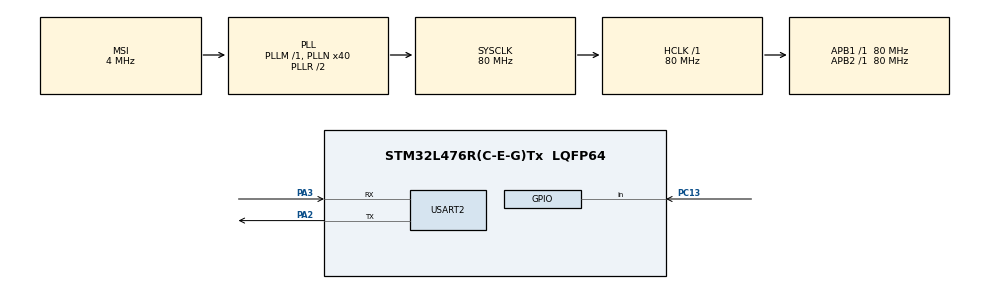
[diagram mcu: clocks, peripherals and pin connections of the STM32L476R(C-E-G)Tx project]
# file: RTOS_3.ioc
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FREERTOS.BinarySemaphores01=BinSem,Dynamic,NULL
FREERTOS.Tasks01=NormalTask,0,128,StartNormalTask,Default,NULL,Dynamic,NULL,NULL;HighTask,1,128,StartHighTask,Default,NULL,Dynamic,NULL,NULL;LowTask,-1,128,StartLowTask,Default,NULL,Dynamic,NULL,NULL
Mcu.Family=STM32L4
Mcu.Name=STM32L476R(C-E-G)Tx
Mcu.Package=LQFP64
NVIC.PriorityGroup=NVIC_PRIORITYGROUP_4
NVIC.TIM1_UP_TIM16_IRQn=true\:0\:0\:false\:false\:true\:false\:false\:true
NVIC.TimeBase=TIM1_UP_TIM16_IRQn
NVIC.TimeBaseIP=TIM1
PA2.Mode=Asynchronous
PA2.Signal=USART2_TX
PA3.Mode=Asynchronous
PA3.Signal=USART2_RX
PC13.Signal=GPIO_Input
ProjectManager.HeapSize=0x200
ProjectManager.StackSize=0x400
ProjectManager.TargetToolchain=TrueSTUDIO
RCC.AHBFreq_Value=80000000
RCC.APB1Freq_Value=80000000
RCC.APB1TimFreq_Value=80000000
RCC.APB2Freq_Value=80000000
RCC.APB2TimFreq_Value=80000000
RCC.CortexFreq_Value=80000000
RCC.HCLKFreq_Value=80000000
RCC.HSE_VALUE=8000000
RCC.HSI_VALUE=16000000
RCC.LSE_VALUE=32768
RCC.MSI_VALUE=4000000
RCC.PLLN=40
RCC.SYSCLKFreq_VALUE=80000000
RCC.SYSCLKSource=RCC_SYSCLKSOURCE_PLLCLK
RCC.VCOOutputFreq_Value=160000000
USART2.VirtualMode-Asynchronous=VM_ASYNC
VP_FREERTOS_VS_CMSIS_V1.Mode=CMSIS_V1
VP_SYS_VS_tim1.Mode=TIM1
board=custom

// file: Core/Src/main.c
/* USER CODE BEGIN Header */
/**
  ******************************************************************************
  * @file           : main.c
  * @brief          : Main program body
  ******************************************************************************
  * @attention
  *
  * <h2><center>&copy; Copyright (c) 2021 STMicroelectronics.
  * All rights reserved.</center></h2>
  *
  * This software component is licensed by ST under Ultimate Liberty license
  * SLA0044, the "License"; You may not use this file except in compliance with
  * the License. You may obtain a copy of the License at:
  *                             www.st.com/SLA0044
  *
  ******************************************************************************
  */
/* USER CODE END Header */
#include "main.h"
#include "cmsis_os.h"

UART_HandleTypeDef huart2;

osThreadId NormalTaskHandle;
osThreadId HighTaskHandle;
osThreadId LowTaskHandle;
osSemaphoreId BinSemHandle;

void SystemClock_Config(void);
static void MX_GPIO_Init(void);
static void MX_USART2_UART_Init(void);
void StartNormalTask(void const * argument);
void StartHighTask(void const * argument);
void StartLowTask(void const * argument);

int main(void)
{

  /* MCU Configuration--------------------------------------------------------*/

  /* Reset of all peripherals, Initializes the Flash interface and the Systick. */
  HAL_Init();

  /* Configure the system clock */
  SystemClock_Config();

  /* Initialize all configured peripherals */
  MX_GPIO_Init();
  MX_USART2_UART_Init();

  /* Create the semaphores(s) */
  /* definition and creation of BinSem */
  osSemaphoreDef(BinSem);
  BinSemHandle = osSemaphoreCreate(osSemaphore(BinSem), 1);

  /* Create the thread(s) */
  /* definition and creation of NormalTask */
  osThreadDef(NormalTask, StartNormalTask, osPriorityNormal, 0, 128);
  NormalTaskHandle = osThreadCreate(osThread(NormalTask), NULL);

  /* definition and creation of HighTask */
  osThreadDef(HighTask, StartHighTask, osPriorityAboveNormal, 0, 128);
  HighTaskHandle = osThreadCreate(osThread(HighTask), NULL);

  /* definition and creation of LowTask */
  osThreadDef(LowTask, StartLowTask, osPriorityBelowNormal, 0, 128);
  LowTaskHandle = osThreadCreate(osThread(LowTask), NULL);

  /* Start scheduler */
  osKernelStart();

  /* We should never get here as control is now taken by the scheduler */
  /* Infinite loop */
  while (1)
  {

  }
}

void SystemClock_Config(void)
{
  RCC_OscInitTypeDef RCC_OscInitStruct = {0};
  RCC_ClkInitTypeDef RCC_ClkInitStruct = {0};
  RCC_PeriphCLKInitTypeDef PeriphClkInit = {0};

  /** Initializes the RCC Oscillators according to the specified parameters
  * in the RCC_OscInitTypeDef structure.
  */
  RCC_OscInitStruct.OscillatorType = RCC_OSCILLATORTYPE_MSI;
  RCC_OscInitStruct.MSIState = RCC_MSI_ON;
  RCC_OscInitStruct.MSICalibrationValue = 0;
  RCC_OscInitStruct.MSIClockRange = RCC_MSIRANGE_6;
  RCC_OscInitStruct.PLL.PLLState = RCC_PLL_ON;
  RCC_OscInitStruct.PLL.PLLSource = RCC_PLLSOURCE_MSI;
  RCC_OscInitStruct.PLL.PLLM = 1;
  RCC_OscInitStruct.PLL.PLLN = 40;
  RCC_OscInitStruct.PLL.PLLP = RCC_PLLP_DIV7;
  RCC_OscInitStruct.PLL.PLLQ = RCC_PLLQ_DIV2;
  RCC_OscInitStruct.PLL.PLLR = RCC_PLLR_DIV2;
  if (HAL_RCC_OscConfig(&RCC_OscInitStruct) != HAL_OK)
  {
    Error_Handler();
  }
  /** Initializes the CPU, AHB and APB buses clocks
  */
  RCC_ClkInitStruct.ClockType = RCC_CLOCKTYPE_HCLK|RCC_CLOCKTYPE_SYSCLK
                              |RCC_CLOCKTYPE_PCLK1|RCC_CLOCKTYPE_PCLK2;
  RCC_ClkInitStruct.SYSCLKSource = RCC_SYSCLKSOURCE_PLLCLK;
  RCC_ClkInitStruct.AHBCLKDivider = RCC_SYSCLK_DIV1;
  RCC_ClkInitStruct.APB1CLKDivider = RCC_HCLK_DIV1;
  RCC_ClkInitStruct.APB2CLKDivider = RCC_HCLK_DIV1;

  if (HAL_RCC_ClockConfig(&RCC_ClkInitStruct, FLASH_LATENCY_4) != HAL_OK)
  {
    Error_Handler();
  }
  PeriphClkInit.PeriphClockSelection = RCC_PERIPHCLK_USART2;
  PeriphClkInit.Usart2ClockSelection = RCC_USART2CLKSOURCE_PCLK1;
  if (HAL_RCCEx_PeriphCLKConfig(&PeriphClkInit) != HAL_OK)
  {
    Error_Handler();
  }
  /** Configure the main internal regulator output voltage
  */
  if (HAL_PWREx_ControlVoltageScaling(PWR_REGULATOR_VOLTAGE_SCALE1) != HAL_OK)
  {
    Error_Handler();
  }
}

static void MX_USART2_UART_Init(void)
{

  huart2.Instance = USART2;
  huart2.Init.BaudRate = 115200;
  huart2.Init.WordLength = UART_WORDLENGTH_8B;
  huart2.Init.StopBits = UART_STOPBITS_1;
  huart2.Init.Parity = UART_PARITY_NONE;
  huart2.Init.Mode = UART_MODE_TX_RX;
  huart2.Init.HwFlowCtl = UART_HWCONTROL_NONE;
  huart2.Init.OverSampling = UART_OVERSAMPLING_16;
  huart2.Init.OneBitSampling = UART_ONE_BIT_SAMPLE_DISABLE;
  huart2.AdvancedInit.AdvFeatureInit = UART_ADVFEATURE_NO_INIT;
  if (HAL_UART_Init(&huart2) != HAL_OK)
  {
    Error_Handler();
  }

}

static void MX_GPIO_Init(void)
{
  GPIO_InitTypeDef GPIO_InitStruct = {0};

  /* GPIO Ports Clock Enable */
  __HAL_RCC_GPIOC_CLK_ENABLE();
  __HAL_RCC_GPIOA_CLK_ENABLE();

  /*Configure GPIO pin : PC13 */
  GPIO_InitStruct.Pin = GPIO_PIN_13;
  GPIO_InitStruct.Mode = GPIO_MODE_INPUT;
  GPIO_InitStruct.Pull = GPIO_NOPULL;
  HAL_GPIO_Init(GPIOC, &GPIO_InitStruct);

}

void StartNormalTask(void const * argument)
{
  /* USER CODE BEGIN 5 */
  /* Infinite loop */
  for(;;)
  {
	  char *str1="Enter NormalTask\r\n";
	  HAL_UART_Transmit(&huart2,(uint8_t *) str1,strlen(str1),100);

	  char *str2="Leaving NormalTask\r\n";
	  HAL_UART_Transmit(&huart2,(uint8_t *) str2,strlen(str2),100);
	  osDelay(500);

  }
  /* USER CODE END 5 */
}

void StartHighTask(void const * argument)
{
  /* USER CODE BEGIN StartHighTask */
  /* Infinite loop */
  for(;;)
  {
	  char *str1="Enter HighTask and waiting for semaphore\r\n";
	  HAL_UART_Transmit(&huart2,(uint8_t *) str1,strlen(str1),100);

	  osSemaphoreWait(BinSemHandle,osWaitForever);
	  char *str3="semaphore acquired by high task\r\n";
	  HAL_UART_Transmit(&huart2,(uint8_t *) str3,strlen(str3),100);

	  char *str2="Leaving HighTask and releasing semaphore\r\n";
	  HAL_UART_Transmit(&huart2,(uint8_t *) str2,strlen(str2),100);

	  osSemaphoreRelease(BinSemHandle);
	  osDelay(500);
  }
  /* USER CODE END StartHighTask */
}

void StartLowTask(void const * argument)
{
  /* USER CODE BEGIN StartLowTask */
  /* Infinite loop */
  for(;;)
  {

	  char *str1="Enter LowTask and waiting for semaphore\r\n";
	  HAL_UART_Transmit(&huart2,(uint8_t *) str1,strlen(str1),100);

	  osSemaphoreWait(BinSemHandle,osWaitForever);
	  char *str3="semaphore acquired by low task\r\n";
	  HAL_UART_Transmit(&huart2,(uint8_t *) str3,strlen(str3),100);

	  while(HAL_GPIO_ReadPin(GPIOC,GPIO_PIN_13));

	  char *str2="Leaving LowTask and releasing semaphore\r\n";
	  HAL_UART_Transmit(&huart2,(uint8_t *) str2,strlen(str2),100);

	  osSemaphoreRelease(BinSemHandle);
	  osDelay(500);
  }
  /* USER CODE END StartLowTask */
}

 /**
  * @brief  Period elapsed callback in non blocking mode
  * @note   This function is called  when TIM1 interrupt took place, inside
  * HAL_TIM_IRQHandler(). It makes a direct call to HAL_IncTick() to increment
  * a global variable "uwTick" used as application time base.
  * @param  htim : TIM handle
  * @retval None
  */
void HAL_TIM_PeriodElapsedCallback(TIM_HandleTypeDef *htim)
{
  if (htim->Instance == TIM1) {
    HAL_IncTick();
  }
}

void Error_Handler(void)
{
  __disable_irq();
  while (1)
  {
  }
}

/************************ (C) COPYRIGHT STMicroelectronics *****END OF FILE****/
